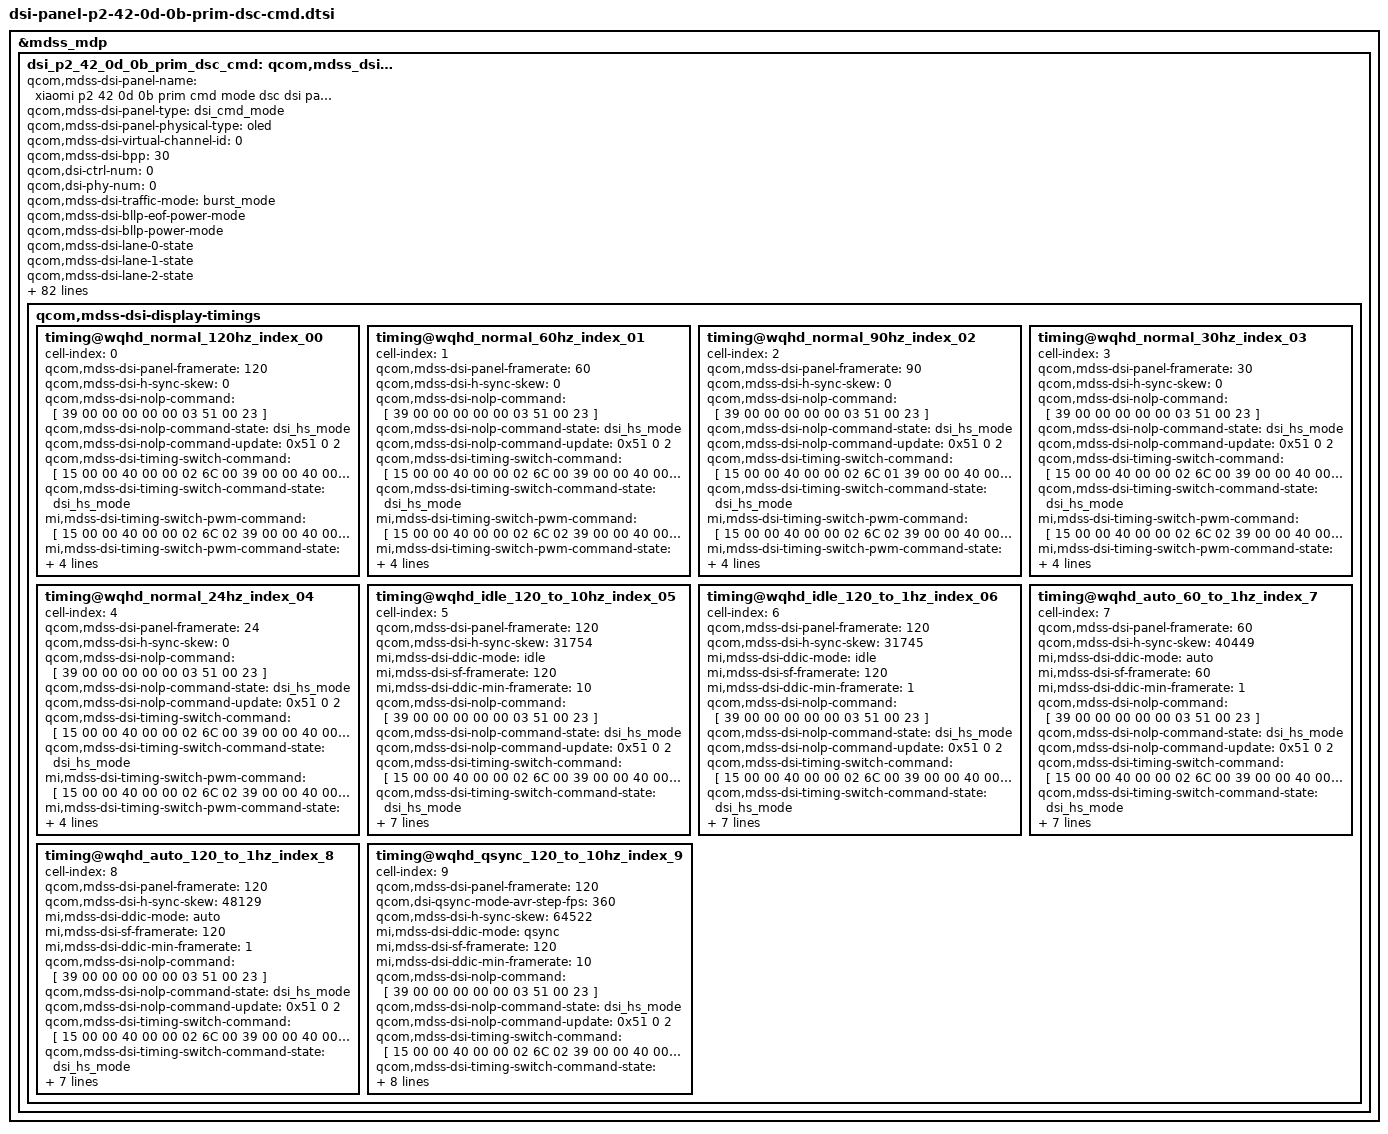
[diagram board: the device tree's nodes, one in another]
&mdss_mdp {
	dsi_p2_42_0d_0b_prim_dsc_cmd: qcom,mdss_dsi_p2_42_0d_0b_prim_dsc_cmd {
		qcom,mdss-dsi-panel-name = "xiaomi p2 42 0d 0b prim cmd mode dsc dsi panel";
		qcom,mdss-dsi-panel-type = "dsi_cmd_mode";
		qcom,mdss-dsi-panel-physical-type = "oled";
		qcom,mdss-dsi-virtual-channel-id = <0>;
		qcom,mdss-dsi-bpp = <30>;
		qcom,dsi-ctrl-num = <0>;
		qcom,dsi-phy-num = <0>;
		qcom,mdss-dsi-traffic-mode = "burst_mode";
		qcom,mdss-dsi-bllp-eof-power-mode;
		qcom,mdss-dsi-bllp-power-mode;
		qcom,mdss-dsi-lane-0-state;
		qcom,mdss-dsi-lane-1-state;
		qcom,mdss-dsi-lane-2-state;
		qcom,mdss-dsi-lane-3-state;
		qcom,mdss-dsi-color-order = "rgb_swap_rgb";
		qcom,mdss-dsi-dma-trigger = "trigger_sw";
		qcom,mdss-dsi-mdp-trigger = "none";
		qcom,mdss-dsi-reset-sequence =<1 1>, <0 1>, <1 10>;
		qcom,mdss-pan-physical-width-dimension = <727>;
		qcom,mdss-pan-physical-height-dimension = <1580>;
		qcom,mdss-dsi-te-pin-select = <1>;
		qcom,mdss-dsi-wr-mem-start = <0x2c>;
		qcom,mdss-dsi-wr-mem-continue = <0x3c>;
		qcom,mdss-dsi-te-dcs-command = <1>;
		qcom,mdss-dsi-tx-eot-append;
		qcom,mdss-dsi-lp11-init;
		qcom,mdss-dsi-bl-inverted-dbv;
		qcom,bl-update-flag = "delay_until_first_frame";
		qcom,mdss-dsi-panel-hdr-enabled;
		qcom,mdss-dsi-panel-hdr-color-primaries = <14500 15500 32000
			17000 15500 30000 8000 3000>;
		qcom,mdss-dsi-panel-peak-brightness = <32000000>;
		qcom,mdss-dsi-panel-blackness-level = <3230>;
		qcom,mdss-dsi-dma-schedule-line = <1>;
		qcom,mdss-dsi-dma-schedule-window = <50>;

		qcom,mdss-disable-cesta-hw-sleep;

		qcom,mdss-dsi-display-timings {
			timing@wqhd_normal_120hz_index_00 {
				#include "dsi-panel-p2-42-0d-0b-prim-dsc-cmd-common.dtsi"
				cell-index = <0>;
				qcom,mdss-dsi-panel-framerate = <120>;
				qcom,mdss-dsi-h-sync-skew = <0>;
				qcom,mdss-dsi-nolp-command = [
					39 00 00 00 00 00 03 51 00 23
				];
				qcom,mdss-dsi-nolp-command-state = "dsi_hs_mode";
				qcom,mdss-dsi-nolp-command-update = <0x51 0 2>;
				qcom,mdss-dsi-timing-switch-command = [
					15 00 00 40 00 00 02 6C 00
					39 00 00 40 00 00 03 75 00 00
					39 00 00 40 00 00 04 71 00 00 00
					39 00 00 40 00 00 03 F0 AA 16
					15 00 00 40 00 00 02 D0 00
					15 00 00 40 00 00 02 65 01
					15 00 00 40 00 00 02 D1 00
					15 00 00 40 00 00 02 D2 01
					15 00 00 40 00 00 02 76 00
					15 00 00 40 00 00 02 77 00
					39 00 00 40 00 00 03 F0 AA 10
					15 00 00 40 00 00 02 CF 17
					39 00 00 00 00 00 03 F0 AA 00
				];
				qcom,mdss-dsi-timing-switch-command-state = "dsi_hs_mode";
				mi,mdss-dsi-timing-switch-pwm-command = [
					15 00 00 40 00 00 02 6C 02
					39 00 00 40 00 00 03 75 00 00
					39 00 00 40 00 00 04 71 00 00 00
					39 00 00 40 00 00 03 F0 AA 16
					15 00 00 40 00 00 02 D0 00
					15 00 00 40 00 00 02 65 07
					15 00 00 40 00 00 02 D1 02
					15 00 00 40 00 00 02 D2 01
					15 00 00 40 00 00 02 65 02
					39 00 00 40 00 00 04 D2 03 65 0F
					15 00 00 40 00 00 02 76 01
					15 00 00 40 00 00 02 77 05
					39 00 00 40 00 00 03 F0 AA 10
					15 00 00 40 00 00 02 CF 09
					39 00 00 00 00 00 03 F0 AA 00
				];
				mi,mdss-dsi-timing-switch-pwm-command-state = "dsi_hs_mode";
				qcom,mdss-dsi-on-command = [
					15 00 00 40 00 00 02 00 00
					15 00 00 40 00 00 02 03 01
					15 00 00 40 00 00 02 35 00
					15 00 00 40 00 00 02 53 20
					39 00 00 40 00 00 03 51 00 00
					15 00 00 40 00 00 02 6F 02
					15 00 00 40 00 00 02 59 00
					15 00 00 40 00 00 02 6C 00
					15 00 00 40 00 00 02 6D 00
					39 00 00 40 00 00 5F 70 11 00 00 89 30 80 0a 30 04 b0
											00 10 02 58 02 58 02 00 02 2c
											00 20 01 98 00 08 00 0c 06 67
											05 b9 18 00 10 f0 03 0c 20 00
											06 0b 0b 33 0e 1c 2a 38 46 54
											62 69 70 77 79 7b 7d 7e 01 02
											01 00 09 40 09 be 19 fc 19 fa
											19 f8 1a 38 1a 78 1a b6 2a b6
											2a f4 2a f4 4b 34 63 74 00 00 00 00 00 00
					39 00 00 40 00 00 03 FF 5A 81
					15 00 00 40 00 00 02 65 03
					15 00 00 40 00 00 02 F3 04
					15 00 00 40 00 00 02 65 05
					15 00 00 40 00 00 02 F3 48
					39 00 00 40 00 00 03 F0 AA 10
					15 00 00 40 00 00 02 65 0A
					15 00 00 40 00 00 02 EB 10
					15 00 00 40 00 00 02 72 00
					39 00 00 40 00 00 03 F0 AA 18
					15 00 00 40 00 00 02 B0 80
					39 00 00 40 00 00 03 F0 AA 00
					39 00 00 40 00 00 03 FF 5A 00
					05 00 00 00 78 00 01 11
					39 00 00 40 00 00 03 F0 AA 10
					15 00 00 40 00 00 02 65 02
					39 00 00 40 00 00 03 CF 24 13
					15 00 00 40 00 00 02 65 0B
					15 00 00 40 00 00 02 CF FF
					39 00 00 00 00 00 03 F0 AA 00
					39 00 00 40 00 00 03 F0 AA 16
					39 00 00 40 00 00 16 E3 00 01 00 00 00 00 00 00 00 00 00 00 00 00 00 00 00 00 00 00 00
					39 00 00 40 00 00 16 E4 00 03 00 00 00 00 00 00 00 00 00 00 00 00 00 00 00 00 00 00 00
					39 00 00 40 00 00 16 E5 00 04 00 00 00 00 00 00 00 00 00 00 00 00 00 00 00 00 00 00 00
					39 00 00 40 00 00 16 E6 01 03 0B 00 00 00 00 00 00 00 00 00 00 00 00 00 00 00 00 00 00
					39 00 00 40 00 00 16 E7 03 03 0B 0B 77 00 00 00 00 0E E0 00 00 00 00 00 00 00 00 00 00
					39 00 00 40 00 00 16 E8 02 0B 0B 77 00 00 00 00 00 EE 00 00 00 00 00 00 00 00 00 00 00
					39 00 00 40 00 00 16 E9 02 08 08 59 00 00 00 00 00 EE 00 00 00 00 00 00 00 00 00 00 00
					39 00 00 40 00 00 16 EA 00 0B 00 00 00 00 00 00 00 00 00 00 00 00 00 00 00 00 00 00 00
					39 00 00 40 00 00 16 EB 02 01 03 EF 00 00 00 00 00 00 00 00 00 00 00 00 00 00 00 00 00
					39 00 00 40 00 00 16 EC 00 01 00 00 00 00 00 00 00 40 00 00 00 00 00 00 00 00 00 00 00
					39 00 00 40 00 00 1F E0 F0 F1 F2 F3 F4 F5 F6 00 00 00 F0 F1 F2 F3 F4 F5 F6 00 00 00 F0 F1 F2 F3 F4 F5 F6 00 00 00
					39 00 00 40 00 00 15 ED F0 F1 F2 F3 F4 F5 F6 F7 F8 00 F0 F1 F2 F3 F4 F5 F6 F7 F8 00
					39 00 00 00 00 00 15 EE F0 F1 F2 F3 F4 F5 F6 F7 F8 00 F0 F1 F2 F3 F4 F5 F6 F7 F8 00
					//Close ELVDD LVD
					39 00 00 40 00 00 03 F0 AA 12
					15 00 00 40 00 00 02 C7 FE
					05 00 00 00 00 00 01 29
					39 00 00 40 00 00 03 F0 AA 10
					15 00 00 40 00 00 02 65 0B
					39 00 00 40 00 00 03 CF DD 79
					39 00 00 00 00 00 03 F0 AA 00
					// FD open
					39 00 00 40 00 00 03 F0 AA 10
					15 00 00 40 00 00 02 D0 A4
					15 00 00 40 00 00 02 65 04
					15 00 00 40 00 00 02 D0 E6
					15 00 00 40 00 00 02 65 13
					39 00 00 00 24 00 03 D8 02 1F
					// FD close
					39 00 00 40 00 00 03 F0 AA 10
					15 00 00 40 00 00 02 D0 84
					39 00 00 00 00 00 03 F0 AA 00
				];
				qcom,mdss-dsi-on-command-state = "dsi_lp_mode";
			};
			timing@wqhd_normal_60hz_index_01 {
				#include "dsi-panel-p2-42-0d-0b-prim-dsc-cmd-common.dtsi"
				cell-index = <1>;
				qcom,mdss-dsi-panel-framerate = <60>;
				qcom,mdss-dsi-h-sync-skew = <0>;
				qcom,mdss-dsi-nolp-command = [
					39 00 00 00 00 00 03 51 00 23
				];
				qcom,mdss-dsi-nolp-command-state = "dsi_hs_mode";
				qcom,mdss-dsi-nolp-command-update = <0x51 0 2>;
				qcom,mdss-dsi-timing-switch-command = [
					15 00 00 40 00 00 02 6C 00
					39 00 00 40 00 00 03 75 C0 00
					39 00 00 40 00 00 04 71 01 00 01
					39 00 00 40 00 00 03 F0 AA 16
					15 00 00 40 00 00 02 D0 00
					15 00 00 40 00 00 02 65 01
					15 00 00 40 00 00 02 D1 00
					15 00 00 40 00 00 02 D2 01
					15 00 00 40 00 00 02 65 02
					39 00 00 40 00 00 04 D2 0A 53 0F
					15 00 00 40 00 00 02 76 01
					15 00 00 40 00 00 02 77 03
					39 00 00 40 00 00 03 F0 AA 10
					15 00 00 40 00 00 02 CF 09
					39 00 00 00 00 00 03 F0 AA 00
				];
				qcom,mdss-dsi-timing-switch-command-state = "dsi_hs_mode";
				mi,mdss-dsi-timing-switch-pwm-command = [
					15 00 00 40 00 00 02 6C 02
					39 00 00 40 00 00 03 75 C0 00
					39 00 00 40 00 00 04 71 01 00 01
					39 00 00 40 00 00 03 F0 AA 16
					15 00 00 40 00 00 02 D0 00
					15 00 00 40 00 00 02 65 07
					15 00 00 40 00 00 02 D1 02
					15 00 00 40 00 00 02 D2 01
					15 00 00 40 00 00 02 65 02
					39 00 00 40 00 00 04 D2 03 65 0F
					15 00 00 40 00 00 02 76 01
					15 00 00 40 00 00 02 77 0B
					39 00 00 40 00 00 03 F0 AA 10
					15 00 00 40 00 00 02 CF 09
					39 00 00 00 00 00 03 F0 AA 00
				];
				mi,mdss-dsi-timing-switch-pwm-command-state = "dsi_hs_mode";
				qcom,mdss-dsi-on-command = [
					15 00 00 40 00 00 02 00 00
					15 00 00 40 00 00 02 03 01
					15 00 00 40 00 00 02 35 00
					15 00 00 40 00 00 02 53 20
					39 00 00 40 00 00 03 51 00 00
					15 00 00 40 00 00 02 6F 02
					15 00 00 40 00 00 02 59 00
					15 00 00 40 00 00 02 6C 00
					15 00 00 40 00 00 02 6D 00
					39 00 00 40 00 00 5F 70 11 00 00 89 30 80 0a 30 04 b0
											00 10 02 58 02 58 02 00 02 2c
											00 20 01 98 00 08 00 0c 06 67
											05 b9 18 00 10 f0 03 0c 20 00
											06 0b 0b 33 0e 1c 2a 38 46 54
											62 69 70 77 79 7b 7d 7e 01 02
											01 00 09 40 09 be 19 fc 19 fa
											19 f8 1a 38 1a 78 1a b6 2a b6
											2a f4 2a f4 4b 34 63 74 00 00 00 00 00 00
					39 00 00 40 00 00 03 FF 5A 81
					15 00 00 40 00 00 02 65 03
					15 00 00 40 00 00 02 F3 04
					15 00 00 40 00 00 02 65 05
					15 00 00 40 00 00 02 F3 48
					39 00 00 40 00 00 03 F0 AA 10
					15 00 00 40 00 00 02 65 0A
					15 00 00 40 00 00 02 EB 10
					15 00 00 40 00 00 02 72 00
					39 00 00 40 00 00 03 F0 AA 18
					15 00 00 40 00 00 02 B0 80
					39 00 00 40 00 00 03 F0 AA 00
					39 00 00 40 00 00 03 FF 5A 00
					05 00 00 00 78 00 01 11
					39 00 00 40 00 00 03 F0 AA 10
					15 00 00 40 00 00 02 65 02
					39 00 00 40 00 00 03 CF 24 13
					15 00 00 40 00 00 02 65 0B
					15 00 00 40 00 00 02 CF FF
					39 00 00 00 00 00 03 F0 AA 00
					39 00 00 40 00 00 03 F0 AA 16
					39 00 00 40 00 00 16 E3 00 01 00 00 00 00 00 00 00 00 00 00 00 00 00 00 00 00 00 00 00
					39 00 00 40 00 00 16 E4 00 03 00 00 00 00 00 00 00 00 00 00 00 00 00 00 00 00 00 00 00
					39 00 00 40 00 00 16 E5 00 04 00 00 00 00 00 00 00 00 00 00 00 00 00 00 00 00 00 00 00
					39 00 00 40 00 00 16 E6 01 03 0B 00 00 00 00 00 00 00 00 00 00 00 00 00 00 00 00 00 00
					39 00 00 40 00 00 16 E7 03 03 0B 0B 77 00 00 00 00 0E E0 00 00 00 00 00 00 00 00 00 00
					39 00 00 40 00 00 16 E8 02 0B 0B 77 00 00 00 00 00 EE 00 00 00 00 00 00 00 00 00 00 00
					39 00 00 40 00 00 16 E9 02 08 08 59 00 00 00 00 00 EE 00 00 00 00 00 00 00 00 00 00 00
					39 00 00 40 00 00 16 EA 00 0B 00 00 00 00 00 00 00 00 00 00 00 00 00 00 00 00 00 00 00
					39 00 00 40 00 00 16 EB 02 01 03 EF 00 00 00 00 00 00 00 00 00 00 00 00 00 00 00 00 00
					39 00 00 40 00 00 16 EC 00 01 00 00 00 00 00 00 00 40 00 00 00 00 00 00 00 00 00 00 00
					39 00 00 40 00 00 1F E0 F0 F1 F2 F3 F4 F5 F6 00 00 00 F0 F1 F2 F3 F4 F5 F6 00 00 00 F0 F1 F2 F3 F4 F5 F6 00 00 00
					39 00 00 40 00 00 15 ED F0 F1 F2 F3 F4 F5 F6 F7 F8 00 F0 F1 F2 F3 F4 F5 F6 F7 F8 00
					39 00 00 00 00 00 15 EE F0 F1 F2 F3 F4 F5 F6 F7 F8 00 F0 F1 F2 F3 F4 F5 F6 F7 F8 00
					//Close ELVDD LVD
					39 00 00 40 00 00 03 F0 AA 12
					15 00 00 40 00 00 02 C7 FE
					05 00 00 00 00 00 01 29
					39 00 00 40 00 00 03 F0 AA 10
					15 00 00 40 00 00 02 65 0B
					39 00 00 40 00 00 03 CF DD 79
					39 00 00 00 00 00 03 F0 AA 00
					// FD open
					39 00 00 40 00 00 03 F0 AA 10
					15 00 00 40 00 00 02 D0 A4
					15 00 00 40 00 00 02 65 04
					15 00 00 40 00 00 02 D0 E6
					15 00 00 40 00 00 02 65 13
					39 00 00 00 24 00 03 D8 02 1F
					// FD close
					39 00 00 40 00 00 03 F0 AA 10
					15 00 00 40 00 00 02 D0 84
					39 00 00 00 00 00 03 F0 AA 00
				];
				qcom,mdss-dsi-on-command-state = "dsi_lp_mode";
			};
			timing@wqhd_normal_90hz_index_02 {
				#include "dsi-panel-p2-42-0d-0b-prim-dsc-cmd-common.dtsi"
				cell-index = <2>;
				qcom,mdss-dsi-panel-framerate = <90>;
				qcom,mdss-dsi-h-sync-skew = <0>;
				qcom,mdss-dsi-nolp-command = [
					39 00 00 00 00 00 03 51 00 23
				];
				qcom,mdss-dsi-nolp-command-state = "dsi_hs_mode";
				qcom,mdss-dsi-nolp-command-update = <0x51 0 2>;
				qcom,mdss-dsi-timing-switch-command = [
					15 00 00 40 00 00 02 6C 01
					39 00 00 40 00 00 03 75 C0 06
					39 00 00 40 00 00 04 71 00 00 00
					39 00 00 40 00 00 03 F0 AA 16
					15 00 00 40 00 00 02 D0 03
					15 00 00 40 00 00 02 65 04
					15 00 00 40 00 00 02 D1 02
					15 00 00 40 00 00 02 D2 01
					15 00 00 40 00 00 02 65 02
					39 00 00 40 00 00 04 D2 0D CA 0F
					15 00 00 40 00 00 02 76 01
					15 00 00 40 00 00 02 77 01
					39 00 00 40 00 00 03 F0 AA 10
					15 00 00 40 00 00 02 CF 09
					39 00 00 00 00 00 03 F0 AA 00
				];
				qcom,mdss-dsi-timing-switch-command-state = "dsi_hs_mode";
				mi,mdss-dsi-timing-switch-pwm-command = [
					15 00 00 40 00 00 02 6C 02
					39 00 00 40 00 00 03 75 C0 00
					39 00 00 40 00 00 04 71 01 10 00
					39 00 00 40 00 00 03 F0 AA 16
					15 00 00 40 00 00 02 D0 00
					15 00 00 40 00 00 02 65 07
					15 00 00 40 00 00 02 D1 02
					15 00 00 40 00 00 02 D2 01
					15 00 00 40 00 00 02 65 02
					39 00 00 40 00 00 04 D2 03 65 0F
					15 00 00 40 00 00 02 76 01
					15 00 00 40 00 00 02 77 07
					39 00 00 40 00 00 03 F0 AA 10
					15 00 00 40 00 00 02 CF 09
					39 00 00 00 00 00 03 F0 AA 00
				];
				mi,mdss-dsi-timing-switch-pwm-command-state = "dsi_hs_mode";
				qcom,mdss-dsi-on-command = [
					15 00 00 40 00 00 02 00 00
					15 00 00 40 00 00 02 03 01
					15 00 00 40 00 00 02 35 00
					15 00 00 40 00 00 02 53 20
					39 00 00 40 00 00 03 51 00 00
					15 00 00 40 00 00 02 6F 02
					15 00 00 40 00 00 02 59 00
					15 00 00 40 00 00 02 6C 00
					15 00 00 40 00 00 02 6D 00
					39 00 00 40 00 00 5F 70 11 00 00 89 30 80 0a 30 04 b0
											00 10 02 58 02 58 02 00 02 2c
											00 20 01 98 00 08 00 0c 06 67
											05 b9 18 00 10 f0 03 0c 20 00
											06 0b 0b 33 0e 1c 2a 38 46 54
											62 69 70 77 79 7b 7d 7e 01 02
											01 00 09 40 09 be 19 fc 19 fa
											19 f8 1a 38 1a 78 1a b6 2a b6
											2a f4 2a f4 4b 34 63 74 00 00 00 00 00 00
					39 00 00 40 00 00 03 FF 5A 81
					15 00 00 40 00 00 02 65 03
					15 00 00 40 00 00 02 F3 04
					15 00 00 40 00 00 02 65 05
					15 00 00 40 00 00 02 F3 48
					39 00 00 40 00 00 03 F0 AA 10
					15 00 00 40 00 00 02 65 0A
					15 00 00 40 00 00 02 EB 10
					15 00 00 40 00 00 02 72 00
					39 00 00 40 00 00 03 F0 AA 18
					15 00 00 40 00 00 02 B0 80
					39 00 00 40 00 00 03 F0 AA 00
					39 00 00 40 00 00 03 FF 5A 00
					05 00 00 00 78 00 01 11
					39 00 00 40 00 00 03 F0 AA 10
					15 00 00 40 00 00 02 65 02
					39 00 00 40 00 00 03 CF 24 13
					15 00 00 40 00 00 02 65 0B
					15 00 00 40 00 00 02 CF FF
					39 00 00 00 00 00 03 F0 AA 00
					39 00 00 40 00 00 03 F0 AA 16
					39 00 00 40 00 00 16 E3 00 01 00 00 00 00 00 00 00 00 00 00 00 00 00 00 00 00 00 00 00
					39 00 00 40 00 00 16 E4 00 03 00 00 00 00 00 00 00 00 00 00 00 00 00 00 00 00 00 00 00
					39 00 00 40 00 00 16 E5 00 04 00 00 00 00 00 00 00 00 00 00 00 00 00 00 00 00 00 00 00
					39 00 00 40 00 00 16 E6 01 03 0B 00 00 00 00 00 00 00 00 00 00 00 00 00 00 00 00 00 00
					39 00 00 40 00 00 16 E7 03 03 0B 0B 77 00 00 00 00 0E E0 00 00 00 00 00 00 00 00 00 00
					39 00 00 40 00 00 16 E8 02 0B 0B 77 00 00 00 00 00 EE 00 00 00 00 00 00 00 00 00 00 00
					39 00 00 40 00 00 16 E9 02 08 08 59 00 00 00 00 00 EE 00 00 00 00 00 00 00 00 00 00 00
					39 00 00 40 00 00 16 EA 00 0B 00 00 00 00 00 00 00 00 00 00 00 00 00 00 00 00 00 00 00
					39 00 00 40 00 00 16 EB 02 01 03 EF 00 00 00 00 00 00 00 00 00 00 00 00 00 00 00 00 00
					39 00 00 40 00 00 16 EC 00 01 00 00 00 00 00 00 00 40 00 00 00 00 00 00 00 00 00 00 00
					39 00 00 40 00 00 1F E0 F0 F1 F2 F3 F4 F5 F6 00 00 00 F0 F1 F2 F3 F4 F5 F6 00 00 00 F0 F1 F2 F3 F4 F5 F6 00 00 00
					39 00 00 40 00 00 15 ED F0 F1 F2 F3 F4 F5 F6 F7 F8 00 F0 F1 F2 F3 F4 F5 F6 F7 F8 00
					39 00 00 00 00 00 15 EE F0 F1 F2 F3 F4 F5 F6 F7 F8 00 F0 F1 F2 F3 F4 F5 F6 F7 F8 00
					//Close ELVDD LVD
					39 00 00 40 00 00 03 F0 AA 12
					15 00 00 40 00 00 02 C7 FE
					05 00 00 00 00 00 01 29
					39 00 00 40 00 00 03 F0 AA 10
					15 00 00 40 00 00 02 65 0B
					39 00 00 40 00 00 03 CF DD 79
					39 00 00 00 00 00 03 F0 AA 00
					// FD open
					39 00 00 40 00 00 03 F0 AA 10
					15 00 00 40 00 00 02 D0 A4
					15 00 00 40 00 00 02 65 04
					15 00 00 40 00 00 02 D0 E6
					15 00 00 40 00 00 02 65 13
					39 00 00 00 24 00 03 D8 02 1F
					// FD close
					39 00 00 40 00 00 03 F0 AA 10
					15 00 00 40 00 00 02 D0 84
					39 00 00 00 00 00 03 F0 AA 00
				];
				qcom,mdss-dsi-on-command-state = "dsi_lp_mode";
			};
			timing@wqhd_normal_30hz_index_03 {
				#include "dsi-panel-p2-42-0d-0b-prim-dsc-cmd-common.dtsi"
				cell-index = <3>;
				qcom,mdss-dsi-panel-framerate = <30>;
				qcom,mdss-dsi-h-sync-skew = <0>;
				qcom,mdss-dsi-nolp-command = [
					39 00 00 00 00 00 03 51 00 23
				];
				qcom,mdss-dsi-nolp-command-state = "dsi_hs_mode";
				qcom,mdss-dsi-nolp-command-update = <0x51 0 2>;
				qcom,mdss-dsi-timing-switch-command = [
					15 00 00 40 00 00 02 6C 00
					39 00 00 40 00 00 03 75 C0 01
					39 00 00 40 00 00 04 71 00 00 00
					39 00 00 40 00 00 03 F0 AA 16
					15 00 00 40 00 00 02 D0 00
					15 00 00 40 00 00 02 65 01
					15 00 00 40 00 00 02 D1 01
					15 00 00 40 00 00 02 D2 01
					15 00 00 40 00 00 02 65 02
					39 00 00 40 00 00 04 D2 0A 53 0F
					15 00 00 40 00 00 02 76 01
					15 00 00 40 00 00 02 77 07
					39 00 00 40 00 00 03 F0 AA 10
					15 00 00 40 00 00 02 CF 09
					39 00 00 00 00 00 03 F0 AA 00
				];
				qcom,mdss-dsi-timing-switch-command-state = "dsi_hs_mode";
				mi,mdss-dsi-timing-switch-pwm-command = [
					15 00 00 40 00 00 02 6C 02
					39 00 00 40 00 00 03 75 C0 01
					39 00 00 40 00 00 04 71 00 00 00
					39 00 00 40 00 00 03 F0 AA 16
					15 00 00 40 00 00 02 D0 00
					15 00 00 40 00 00 02 65 07
					15 00 00 40 00 00 02 D1 05
					15 00 00 40 00 00 02 D2 01
					15 00 00 40 00 00 02 65 02
					39 00 00 40 00 00 04 D2 03 65 0F
					15 00 00 40 00 00 02 76 01
					15 00 00 40 00 00 02 77 17
					39 00 00 40 00 00 03 F0 AA 10
					15 00 00 40 00 00 02 CF 09
					39 00 00 00 00 00 03 F0 AA 00
				];
				mi,mdss-dsi-timing-switch-pwm-command-state = "dsi_hs_mode";
				qcom,mdss-dsi-on-command = [
					15 00 00 40 00 00 02 00 00
					15 00 00 40 00 00 02 03 01
					15 00 00 40 00 00 02 35 00
					15 00 00 40 00 00 02 53 20
					39 00 00 40 00 00 03 51 00 00
					15 00 00 40 00 00 02 6F 02
					15 00 00 40 00 00 02 59 00
					15 00 00 40 00 00 02 6C 00
					15 00 00 40 00 00 02 6D 00
					39 00 00 40 00 00 5F 70 11 00 00 89 30 80 0a 30 04 b0
											00 10 02 58 02 58 02 00 02 2c
											00 20 01 98 00 08 00 0c 06 67
											05 b9 18 00 10 f0 03 0c 20 00
											06 0b 0b 33 0e 1c 2a 38 46 54
											62 69 70 77 79 7b 7d 7e 01 02
											01 00 09 40 09 be 19 fc 19 fa
											19 f8 1a 38 1a 78 1a b6 2a b6
											2a f4 2a f4 4b 34 63 74 00 00 00 00 00 00
					39 00 00 40 00 00 03 FF 5A 81
					15 00 00 40 00 00 02 65 03
					15 00 00 40 00 00 02 F3 04
					15 00 00 40 00 00 02 65 05
					15 00 00 40 00 00 02 F3 48
					39 00 00 40 00 00 03 F0 AA 10
					15 00 00 40 00 00 02 65 0A
					15 00 00 40 00 00 02 EB 10
					15 00 00 40 00 00 02 72 00
					39 00 00 40 00 00 03 F0 AA 18
					15 00 00 40 00 00 02 B0 80
					39 00 00 40 00 00 03 F0 AA 00
					39 00 00 40 00 00 03 FF 5A 00
					05 00 00 00 78 00 01 11
					39 00 00 40 00 00 03 F0 AA 10
					15 00 00 40 00 00 02 65 02
					39 00 00 40 00 00 03 CF 24 13
					15 00 00 40 00 00 02 65 0B
					15 00 00 40 00 00 02 CF FF
					39 00 00 00 00 00 03 F0 AA 00
					39 00 00 40 00 00 03 F0 AA 16
					39 00 00 40 00 00 16 E3 00 01 00 00 00 00 00 00 00 00 00 00 00 00 00 00 00 00 00 00 00
					39 00 00 40 00 00 16 E4 00 03 00 00 00 00 00 00 00 00 00 00 00 00 00 00 00 00 00 00 00
					39 00 00 40 00 00 16 E5 00 04 00 00 00 00 00 00 00 00 00 00 00 00 00 00 00 00 00 00 00
					39 00 00 40 00 00 16 E6 01 03 0B 00 00 00 00 00 00 00 00 00 00 00 00 00 00 00 00 00 00
					39 00 00 40 00 00 16 E7 03 03 0B 0B 77 00 00 00 00 0E E0 00 00 00 00 00 00 00 00 00 00
					39 00 00 40 00 00 16 E8 02 0B 0B 77 00 00 00 00 00 EE 00 00 00 00 00 00 00 00 00 00 00
					39 00 00 40 00 00 16 E9 02 08 08 59 00 00 00 00 00 EE 00 00 00 00 00 00 00 00 00 00 00
					39 00 00 40 00 00 16 EA 00 0B 00 00 00 00 00 00 00 00 00 00 00 00 00 00 00 00 00 00 00
					39 00 00 40 00 00 16 EB 02 01 03 EF 00 00 00 00 00 00 00 00 00 00 00 00 00 00 00 00 00
					39 00 00 40 00 00 16 EC 00 01 00 00 00 00 00 00 00 40 00 00 00 00 00 00 00 00 00 00 00
					39 00 00 40 00 00 1F E0 F0 F1 F2 F3 F4 F5 F6 00 00 00 F0 F1 F2 F3 F4 F5 F6 00 00 00 F0 F1 F2 F3 F4 F5 F6 00 00 00
					39 00 00 40 00 00 15 ED F0 F1 F2 F3 F4 F5 F6 F7 F8 00 F0 F1 F2 F3 F4 F5 F6 F7 F8 00
					39 00 00 00 00 00 15 EE F0 F1 F2 F3 F4 F5 F6 F7 F8 00 F0 F1 F2 F3 F4 F5 F6 F7 F8 00
					//Close ELVDD LVD
					39 00 00 40 00 00 03 F0 AA 12
					15 00 00 40 00 00 02 C7 FE
					05 00 00 00 00 00 01 29
					39 00 00 40 00 00 03 F0 AA 10
					15 00 00 40 00 00 02 65 0B
					39 00 00 40 00 00 03 CF DD 79
					39 00 00 00 00 00 03 F0 AA 00
					// FD open
					39 00 00 40 00 00 03 F0 AA 10
					15 00 00 40 00 00 02 D0 A4
					15 00 00 40 00 00 02 65 04
					15 00 00 40 00 00 02 D0 E6
					15 00 00 40 00 00 02 65 13
					39 00 00 00 24 00 03 D8 02 1F
					// FD close
					39 00 00 40 00 00 03 F0 AA 10
					15 00 00 40 00 00 02 D0 84
					39 00 00 00 00 00 03 F0 AA 00
				];
				qcom,mdss-dsi-on-command-state = "dsi_lp_mode";
			};
			timing@wqhd_normal_24hz_index_04 {
				#include "dsi-panel-p2-42-0d-0b-prim-dsc-cmd-common.dtsi"
				cell-index = <4>;
				qcom,mdss-dsi-panel-framerate = <24>;
				qcom,mdss-dsi-h-sync-skew = <0>;
				qcom,mdss-dsi-nolp-command = [
					39 00 00 00 00 00 03 51 00 23
				];
				qcom,mdss-dsi-nolp-command-state = "dsi_hs_mode";
				qcom,mdss-dsi-nolp-command-update = <0x51 0 2>;
				qcom,mdss-dsi-timing-switch-command = [
					15 00 00 40 00 00 02 6C 00
					39 00 00 40 00 00 03 75 C0 02
					39 00 00 40 00 00 04 71 00 00 00
					39 00 00 40 00 00 03 F0 AA 16
					15 00 00 40 00 00 02 D0 00
					15 00 00 40 00 00 02 65 01
					15 00 00 40 00 00 02 D1 01
					15 00 00 40 00 00 02 D2 01
					15 00 00 40 00 00 02 65 02
					39 00 00 40 00 00 04 D2 0A 53 0F
					15 00 00 40 00 00 02 76 01
					15 00 00 40 00 00 02 77 09
					39 00 00 40 00 00 03 F0 AA 10
					15 00 00 40 00 00 02 CF 09
					39 00 00 00 00 00 03 F0 AA 00
				];
				qcom,mdss-dsi-timing-switch-command-state = "dsi_hs_mode";
				mi,mdss-dsi-timing-switch-pwm-command = [
					15 00 00 40 00 00 02 6C 02
					39 00 00 40 00 00 03 75 C0 02
					39 00 00 40 00 00 04 71 00 00 00
					39 00 00 40 00 00 03 F0 AA 16
					15 00 00 40 00 00 02 D0 00
					15 00 00 40 00 00 02 65 07
					15 00 00 40 00 00 02 D1 0B
					15 00 00 40 00 00 02 D2 01
					15 00 00 40 00 00 02 65 02
					39 00 00 40 00 00 04 D2 03 65 0F
					15 00 00 40 00 00 02 76 01
					15 00 00 40 00 00 02 77 1D
					39 00 00 40 00 00 03 F0 AA 10
					15 00 00 40 00 00 02 CF 09
					39 00 00 00 00 00 03 F0 AA 00
				];
				mi,mdss-dsi-timing-switch-pwm-command-state = "dsi_hs_mode";
				qcom,mdss-dsi-on-command = [
					15 00 00 40 00 00 02 00 00
					15 00 00 40 00 00 02 03 01
					15 00 00 40 00 00 02 35 00
					15 00 00 40 00 00 02 53 20
					39 00 00 40 00 00 03 51 00 00
					15 00 00 40 00 00 02 6F 02
					15 00 00 40 00 00 02 59 00
					15 00 00 40 00 00 02 6C 00
					15 00 00 40 00 00 02 6D 00
					39 00 00 40 00 00 5F 70 11 00 00 89 30 80 0a 30 04 b0
											00 10 02 58 02 58 02 00 02 2c
											00 20 01 98 00 08 00 0c 06 67
											05 b9 18 00 10 f0 03 0c 20 00
											06 0b 0b 33 0e 1c 2a 38 46 54
											62 69 70 77 79 7b 7d 7e 01 02
											01 00 09 40 09 be 19 fc 19 fa
											19 f8 1a 38 1a 78 1a b6 2a b6
											2a f4 2a f4 4b 34 63 74 00 00 00 00 00 00
					39 00 00 40 00 00 03 FF 5A 81
					15 00 00 40 00 00 02 65 03
					15 00 00 40 00 00 02 F3 04
					15 00 00 40 00 00 02 65 05
					15 00 00 40 00 00 02 F3 48
					39 00 00 40 00 00 03 F0 AA 10
					15 00 00 40 00 00 02 65 0A
					15 00 00 40 00 00 02 EB 10
					15 00 00 40 00 00 02 72 00
					39 00 00 40 00 00 03 F0 AA 18
					15 00 00 40 00 00 02 B0 80
					39 00 00 40 00 00 03 F0 AA 00
					39 00 00 40 00 00 03 FF 5A 00
					05 00 00 00 78 00 01 11
					39 00 00 40 00 00 03 F0 AA 10
					15 00 00 40 00 00 02 65 02
					39 00 00 40 00 00 03 CF 24 13
					15 00 00 40 00 00 02 65 0B
					15 00 00 40 00 00 02 CF FF
					39 00 00 00 00 00 03 F0 AA 00
					39 00 00 40 00 00 03 F0 AA 16
					39 00 00 40 00 00 16 E3 00 01 00 00 00 00 00 00 00 00 00 00 00 00 00 00 00 00 00 00 00
					39 00 00 40 00 00 16 E4 00 03 00 00 00 00 00 00 00 00 00 00 00 00 00 00 00 00 00 00 00
					39 00 00 40 00 00 16 E5 00 04 00 00 00 00 00 00 00 00 00 00 00 00 00 00 00 00 00 00 00
					39 00 00 40 00 00 16 E6 01 03 0B 00 00 00 00 00 00 00 00 00 00 00 00 00 00 00 00 00 00
					39 00 00 40 00 00 16 E7 03 03 0B 0B 77 00 00 00 00 0E E0 00 00 00 00 00 00 00 00 00 00
					39 00 00 40 00 00 16 E8 02 0B 0B 77 00 00 00 00 00 EE 00 00 00 00 00 00 00 00 00 00 00
					39 00 00 40 00 00 16 E9 02 08 08 59 00 00 00 00 00 EE 00 00 00 00 00 00 00 00 00 00 00
					39 00 00 40 00 00 16 EA 00 0B 00 00 00 00 00 00 00 00 00 00 00 00 00 00 00 00 00 00 00
					39 00 00 40 00 00 16 EB 02 01 03 EF 00 00 00 00 00 00 00 00 00 00 00 00 00 00 00 00 00
					39 00 00 40 00 00 16 EC 00 01 00 00 00 00 00 00 00 40 00 00 00 00 00 00 00 00 00 00 00
					39 00 00 40 00 00 1F E0 F0 F1 F2 F3 F4 F5 F6 00 00 00 F0 F1 F2 F3 F4 F5 F6 00 00 00 F0 F1 F2 F3 F4 F5 F6 00 00 00
					39 00 00 40 00 00 15 ED F0 F1 F2 F3 F4 F5 F6 F7 F8 00 F0 F1 F2 F3 F4 F5 F6 F7 F8 00
					39 00 00 00 00 00 15 EE F0 F1 F2 F3 F4 F5 F6 F7 F8 00 F0 F1 F2 F3 F4 F5 F6 F7 F8 00
					//Close ELVDD LVD
					39 00 00 40 00 00 03 F0 AA 12
					15 00 00 40 00 00 02 C7 FE
					05 00 00 00 00 00 01 29
					39 00 00 40 00 00 03 F0 AA 10
					15 00 00 40 00 00 02 65 0B
					39 00 00 40 00 00 03 CF DD 79
					39 00 00 00 00 00 03 F0 AA 00
					// FD open
					39 00 00 40 00 00 03 F0 AA 10
					15 00 00 40 00 00 02 D0 A4
					15 00 00 40 00 00 02 65 04
					15 00 00 40 00 00 02 D0 E6
					15 00 00 40 00 00 02 65 13
					39 00 00 00 24 00 03 D8 02 1F
					// FD close
					39 00 00 40 00 00 03 F0 AA 10
					15 00 00 40 00 00 02 D0 84
					39 00 00 00 00 00 03 F0 AA 00
				];
				qcom,mdss-dsi-on-command-state = "dsi_lp_mode";
			};
			timing@wqhd_idle_120_to_10hz_index_05 {
				#include "dsi-panel-p2-42-0d-0b-prim-dsc-cmd-common.dtsi"
				cell-index = <5>;
				qcom,mdss-dsi-panel-framerate = <120>;
				/* ---------------------------- */
				/* | 15 - 14 | 13 - 7 | 6 - 0 | */
				/* ---------------------------- */
				/* |   mode  | sf fps | min fps| */
				/* ---------------------------- -*/
				/* mode: 1 idle, 2 auto, 3 qsync */
				/*   1 << 14 | 120 << 7 | 10     */
				qcom,mdss-dsi-h-sync-skew = <31754>;
				/* mode: 0 normal, 1 idle, 2 auto, 3 qsync, 4 diff, 5 test */
				mi,mdss-dsi-ddic-mode = "idle";
				mi,mdss-dsi-sf-framerate = <120>;
				mi,mdss-dsi-ddic-min-framerate = <10>;
				qcom,mdss-dsi-nolp-command = [
					39 00 00 00 00 00 03 51 00 23
				];
				qcom,mdss-dsi-nolp-command-state = "dsi_hs_mode";
				qcom,mdss-dsi-nolp-command-update = <0x51 0 2>;
				qcom,mdss-dsi-timing-switch-command = [
					15 00 00 40 00 00 02 6C 00
					39 00 00 40 00 00 03 75 C0 03
					39 00 00 40 00 00 04 71 00 00 00
					39 00 00 40 00 00 03 F0 AA 16
					15 00 00 40 00 00 02 D0 03
					15 00 00 40 00 00 02 65 01
					15 00 00 40 00 00 02 D1 01
					15 00 00 40 00 00 02 D2 01
					15 00 00 40 00 00 02 65 02
					39 00 00 40 00 00 04 D2 0A 53 0F
					15 00 00 40 00 00 02 76 01
					15 00 00 40 00 00 02 77 01
					39 00 00 40 00 00 03 F0 AA 10
					15 00 00 40 00 00 02 CF 09
					39 00 00 00 00 00 03 F0 AA 00
				];
				qcom,mdss-dsi-timing-switch-command-state = "dsi_hs_mode";
				mi,mdss-dsi-timing-switch-pwm-command = [
					15 00 00 40 00 00 02 6C 02
					39 00 00 40 00 00 03 75 C0 07
					39 00 00 40 00 00 04 71 00 00 00
					39 00 00 40 00 00 03 F0 AA 16
					15 00 00 40 00 00 02 D0 03
					15 00 00 40 00 00 02 65 07
					15 00 00 40 00 00 02 D1 0B
					15 00 00 40 00 00 02 D2 01
					15 00 00 40 00 00 02 65 02
					39 00 00 40 00 00 04 D2 03 65 0F
					15 00 00 40 00 00 02 76 01
					15 00 00 40 00 00 02 77 05
					39 00 00 40 00 00 03 F0 AA 10
					15 00 00 40 00 00 02 CF 09
					39 00 00 00 00 00 03 F0 AA 00
				];
				mi,mdss-dsi-timing-switch-pwm-command-state = "dsi_hs_mode";
				qcom,mdss-dsi-on-command = [
					15 00 00 40 00 00 02 00 00
					15 00 00 40 00 00 02 03 01
					15 00 00 40 00 00 02 35 00
					15 00 00 40 00 00 02 53 20
					39 00 00 40 00 00 03 51 00 00
					15 00 00 40 00 00 02 6F 02
					15 00 00 40 00 00 02 59 00
					15 00 00 40 00 00 02 6C 00
					15 00 00 40 00 00 02 6D 00
					39 00 00 40 00 00 5F 70 11 00 00 89 30 80 0a 30 04 b0
											00 10 02 58 02 58 02 00 02 2c
											00 20 01 98 00 08 00 0c 06 67
											05 b9 18 00 10 f0 03 0c 20 00
											06 0b 0b 33 0e 1c 2a 38 46 54
											62 69 70 77 79 7b 7d 7e 01 02
											01 00 09 40 09 be 19 fc 19 fa
											19 f8 1a 38 1a 78 1a b6 2a b6
											2a f4 2a f4 4b 34 63 74 00 00 00 00 00 00
					39 00 00 40 00 00 03 FF 5A 81
					15 00 00 40 00 00 02 65 03
					15 00 00 40 00 00 02 F3 04
					15 00 00 40 00 00 02 65 05
					15 00 00 40 00 00 02 F3 48
					39 00 00 40 00 00 03 F0 AA 10
					15 00 00 40 00 00 02 65 0A
					15 00 00 40 00 00 02 EB 10
					15 00 00 40 00 00 02 72 00
					39 00 00 40 00 00 03 F0 AA 18
					15 00 00 40 00 00 02 B0 80
					39 00 00 40 00 00 03 F0 AA 00
					39 00 00 40 00 00 03 FF 5A 00
					05 00 00 00 78 00 01 11
					39 00 00 40 00 00 03 F0 AA 10
					15 00 00 40 00 00 02 65 02
					39 00 00 40 00 00 03 CF 24 13
					15 00 00 40 00 00 02 65 0B
					15 00 00 40 00 00 02 CF FF
					39 00 00 00 00 00 03 F0 AA 00
					39 00 00 40 00 00 03 F0 AA 16
					39 00 00 40 00 00 16 E3 00 01 00 00 00 00 00 00 00 00 00 00 00 00 00 00 00 00 00 00 00
					39 00 00 40 00 00 16 E4 00 03 00 00 00 00 00 00 00 00 00 00 00 00 00 00 00 00 00 00 00
					39 00 00 40 00 00 16 E5 00 04 00 00 00 00 00 00 00 00 00 00 00 00 00 00 00 00 00 00 00
					39 00 00 40 00 00 16 E6 01 03 0B 00 00 00 00 00 00 00 00 00 00 00 00 00 00 00 00 00 00
					39 00 00 40 00 00 16 E7 03 03 0B 0B 77 00 00 00 00 0E E0 00 00 00 00 00 00 00 00 00 00
					39 00 00 40 00 00 16 E8 02 0B 0B 77 00 00 00 00 00 EE 00 00 00 00 00 00 00 00 00 00 00
					39 00 00 40 00 00 16 E9 02 08 08 59 00 00 00 00 00 EE 00 00 00 00 00 00 00 00 00 00 00
					39 00 00 40 00 00 16 EA 00 0B 00 00 00 00 00 00 00 00 00 00 00 00 00 00 00 00 00 00 00
					39 00 00 40 00 00 16 EB 02 01 03 EF 00 00 00 00 00 00 00 00 00 00 00 00 00 00 00 00 00
					39 00 00 40 00 00 16 EC 00 01 00 00 00 00 00 00 00 40 00 00 00 00 00 00 00 00 00 00 00
					39 00 00 40 00 00 1F E0 F0 F1 F2 F3 F4 F5 F6 00 00 00 F0 F1 F2 F3 F4 F5 F6 00 00 00 F0 F1 F2 F3 F4 F5 F6 00 00 00
					39 00 00 40 00 00 15 ED F0 F1 F2 F3 F4 F5 F6 F7 F8 00 F0 F1 F2 F3 F4 F5 F6 F7 F8 00
					39 00 00 00 00 00 15 EE F0 F1 F2 F3 F4 F5 F6 F7 F8 00 F0 F1 F2 F3 F4 F5 F6 F7 F8 00
					//Close ELVDD LVD
					39 00 00 40 00 00 03 F0 AA 12
					15 00 00 40 00 00 02 C7 FE
					05 00 00 00 00 00 01 29
					39 00 00 40 00 00 03 F0 AA 10
					15 00 00 40 00 00 02 65 0B
					39 00 00 40 00 00 03 CF DD 79
					39 00 00 00 00 00 03 F0 AA 00
					// FD open
					39 00 00 40 00 00 03 F0 AA 10
					15 00 00 40 00 00 02 D0 A4
					15 00 00 40 00 00 02 65 04
					15 00 00 40 00 00 02 D0 E6
					15 00 00 40 00 00 02 65 13
					39 00 00 00 24 00 03 D8 02 1F
					// FD close
					39 00 00 40 00 00 03 F0 AA 10
					15 00 00 40 00 00 02 D0 84
					39 00 00 00 00 00 03 F0 AA 00
				];
				qcom,mdss-dsi-on-command-state = "dsi_lp_mode";
			};
			timing@wqhd_idle_120_to_1hz_index_06 {
				#include "dsi-panel-p2-42-0d-0b-prim-dsc-cmd-common.dtsi"
				cell-index = <6>;
				qcom,mdss-dsi-panel-framerate = <120>;
				/* ---------------------------- */
				/* | 15 - 14 | 13 - 7 | 6 - 0 | */
				/* ---------------------------- */
				/* |   mode  | sf fps | min fps| */
				/* ---------------------------- -*/
				/* mode: 1 idle, 2 auto, 3 qsync */
				/*   1 << 14 | 120 << 7 | 1     */
				qcom,mdss-dsi-h-sync-skew = <31745>;
				/* mode: 0 normal, 1 idle, 2 auto, 3 qsync, 4 diff, 5 test */
				mi,mdss-dsi-ddic-mode = "idle";
				mi,mdss-dsi-sf-framerate = <120>;
				mi,mdss-dsi-ddic-min-framerate = <1>;
				qcom,mdss-dsi-nolp-command = [
					39 00 00 00 00 00 03 51 00 23
				];
				qcom,mdss-dsi-nolp-command-state = "dsi_hs_mode";
				qcom,mdss-dsi-nolp-command-update = <0x51 0 2>;
				qcom,mdss-dsi-timing-switch-command = [
					15 00 00 40 00 00 02 6C 00
					39 00 00 40 00 00 03 75 C0 04
					39 00 00 40 00 00 04 71 00 00 00
					39 00 00 40 00 00 03 F0 AA 16
					15 00 00 40 00 00 02 D0 03
					15 00 00 40 00 00 02 65 01
					15 00 00 40 00 00 02 D1 01
					15 00 00 40 00 00 02 D2 01
					15 00 00 40 00 00 02 65 02
					39 00 00 40 00 00 04 D2 0A 53 0F
					15 00 00 40 00 00 02 76 01
					15 00 00 40 00 00 02 77 01
					39 00 00 40 00 00 03 F0 AA 10
					15 00 00 40 00 00 02 CF 09
					39 00 00 00 00 00 03 F0 AA 00
				];
				qcom,mdss-dsi-timing-switch-command-state = "dsi_hs_mode";
				mi,mdss-dsi-timing-switch-pwm-command = [
					15 00 00 40 00 00 02 6C 02
					39 00 00 40 00 00 03 75 C0 05
					39 00 00 40 00 00 04 71 00 00 00
					39 00 00 40 00 00 03 F0 AA 16
					15 00 00 40 00 00 02 D0 03
					15 00 00 40 00 00 02 65 07
					15 00 00 40 00 00 02 D1 0B
					15 00 00 40 00 00 02 D2 01
					15 00 00 40 00 00 02 65 02
					39 00 00 40 00 00 04 D2 03 65 0F
					15 00 00 40 00 00 02 76 01
					15 00 00 40 00 00 02 77 05
					39 00 00 40 00 00 03 F0 AA 10
					15 00 00 40 00 00 02 CF 09
					39 00 00 00 00 00 03 F0 AA 00
				];
				mi,mdss-dsi-timing-switch-pwm-command-state = "dsi_hs_mode";
				qcom,mdss-dsi-on-command = [
					15 00 00 40 00 00 02 00 00
					15 00 00 40 00 00 02 03 01
					15 00 00 40 00 00 02 35 00
					15 00 00 40 00 00 02 53 20
					39 00 00 40 00 00 03 51 00 00
					15 00 00 40 00 00 02 6F 02
					15 00 00 40 00 00 02 59 00
					15 00 00 40 00 00 02 6C 00
					15 00 00 40 00 00 02 6D 00
					39 00 00 40 00 00 5F 70 11 00 00 89 30 80 0a 30 04 b0
											00 10 02 58 02 58 02 00 02 2c
											00 20 01 98 00 08 00 0c 06 67
											05 b9 18 00 10 f0 03 0c 20 00
											06 0b 0b 33 0e 1c 2a 38 46 54
											62 69 70 77 79 7b 7d 7e 01 02
											01 00 09 40 09 be 19 fc 19 fa
											19 f8 1a 38 1a 78 1a b6 2a b6
											2a f4 2a f4 4b 34 63 74 00 00 00 00 00 00
					39 00 00 40 00 00 03 FF 5A 81
					15 00 00 40 00 00 02 65 03
					15 00 00 40 00 00 02 F3 04
					15 00 00 40 00 00 02 65 05
					15 00 00 40 00 00 02 F3 48
					39 00 00 40 00 00 03 F0 AA 10
					15 00 00 40 00 00 02 65 0A
					15 00 00 40 00 00 02 EB 10
					15 00 00 40 00 00 02 72 00
					39 00 00 40 00 00 03 F0 AA 18
					15 00 00 40 00 00 02 B0 80
					39 00 00 40 00 00 03 F0 AA 00
					39 00 00 40 00 00 03 FF 5A 00
					05 00 00 00 78 00 01 11
					39 00 00 40 00 00 03 F0 AA 10
					15 00 00 40 00 00 02 65 02
					39 00 00 40 00 00 03 CF 24 13
					15 00 00 40 00 00 02 65 0B
					15 00 00 40 00 00 02 CF FF
					39 00 00 00 00 00 03 F0 AA 00
					39 00 00 40 00 00 03 F0 AA 16
					39 00 00 40 00 00 16 E3 00 01 00 00 00 00 00 00 00 00 00 00 00 00 00 00 00 00 00 00 00
					39 00 00 40 00 00 16 E4 00 03 00 00 00 00 00 00 00 00 00 00 00 00 00 00 00 00 00 00 00
					39 00 00 40 00 00 16 E5 00 04 00 00 00 00 00 00 00 00 00 00 00 00 00 00 00 00 00 00 00
					39 00 00 40 00 00 16 E6 01 03 0B 00 00 00 00 00 00 00 00 00 00 00 00 00 00 00 00 00 00
					39 00 00 40 00 00 16 E7 03 03 0B 0B 77 00 00 00 00 0E E0 00 00 00 00 00 00 00 00 00 00
					39 00 00 40 00 00 16 E8 02 0B 0B 77 00 00 00 00 00 EE 00 00 00 00 00 00 00 00 00 00 00
					39 00 00 40 00 00 16 E9 02 08 08 59 00 00 00 00 00 EE 00 00 00 00 00 00 00 00 00 00 00
					39 00 00 40 00 00 16 EA 00 0B 00 00 00 00 00 00 00 00 00 00 00 00 00 00 00 00 00 00 00
					39 00 00 40 00 00 16 EB 02 01 03 EF 00 00 00 00 00 00 00 00 00 00 00 00 00 00 00 00 00
					39 00 00 40 00 00 16 EC 00 01 00 00 00 00 00 00 00 40 00 00 00 00 00 00 00 00 00 00 00
					39 00 00 40 00 00 1F E0 F0 F1 F2 F3 F4 F5 F6 00 00 00 F0 F1 F2 F3 F4 F5 F6 00 00 00 F0 F1 F2 F3 F4 F5 F6 00 00 00
					39 00 00 40 00 00 15 ED F0 F1 F2 F3 F4 F5 F6 F7 F8 00 F0 F1 F2 F3 F4 F5 F6 F7 F8 00
					39 00 00 00 00 00 15 EE F0 F1 F2 F3 F4 F5 F6 F7 F8 00 F0 F1 F2 F3 F4 F5 F6 F7 F8 00
					//Close ELVDD LVD
					39 00 00 40 00 00 03 F0 AA 12
					15 00 00 40 00 00 02 C7 FE
					05 00 00 00 00 00 01 29
					39 00 00 40 00 00 03 F0 AA 10
					15 00 00 40 00 00 02 65 0B
					39 00 00 40 00 00 03 CF DD 79
					39 00 00 00 00 00 03 F0 AA 00
					// FD open
					39 00 00 40 00 00 03 F0 AA 10
					15 00 00 40 00 00 02 D0 A4
					15 00 00 40 00 00 02 65 04
					15 00 00 40 00 00 02 D0 E6
					15 00 00 40 00 00 02 65 13
					39 00 00 00 24 00 03 D8 02 1F
					// FD close
					39 00 00 40 00 00 03 F0 AA 10
					15 00 00 40 00 00 02 D0 84
					39 00 00 00 00 00 03 F0 AA 00
				];
				qcom,mdss-dsi-on-command-state = "dsi_lp_mode";
			};
			timing@wqhd_auto_60_to_1hz_index_7 {
				#include "dsi-panel-p2-42-0d-0b-prim-dsc-cmd-common.dtsi"
				cell-index = <7>;
				qcom,mdss-dsi-panel-framerate = <60>;
				/* ---------------------------- */
				/* | 15 - 14 | 13 - 7 | 6 - 0 | */
				/* ---------------------------- */
				/* |   mode  | sf fps | min fps| */
				/* ---------------------------- -*/
				/* mode: 1 idle, 2 auto, 3 qsync */
				/*   2 << 14 | 60 << 7 | 1     */
				qcom,mdss-dsi-h-sync-skew = <40449>;
				/* mode: 0 normal, 1 idle, 2 auto, 3 qsync, 4 diff, 5 test */
				mi,mdss-dsi-ddic-mode = "auto";
				mi,mdss-dsi-sf-framerate = <60>;
				mi,mdss-dsi-ddic-min-framerate = <1>;
				qcom,mdss-dsi-nolp-command = [
					39 00 00 00 00 00 03 51 00 23
				];
				qcom,mdss-dsi-nolp-command-state = "dsi_hs_mode";
				qcom,mdss-dsi-nolp-command-update = <0x51 0 2>;
				qcom,mdss-dsi-timing-switch-command = [
					15 00 00 40 00 00 02 6C 00
					39 00 00 40 00 00 03 75 C0 05
					39 00 00 40 00 00 04 71 00 00 00
					39 00 00 40 00 00 03 F0 AA 16
					15 00 00 40 00 00 02 D0 01
					15 00 00 40 00 00 02 65 01
					15 00 00 40 00 00 02 D1 03
					15 00 00 40 00 00 02 D2 01
					15 00 00 40 00 00 02 65 02
					39 00 00 40 00 00 04 D2 0A 53 0F
					15 00 00 40 00 00 02 76 01
					15 00 00 40 00 00 02 77 03
					39 00 00 40 00 00 03 F0 AA 10
					15 00 00 40 00 00 02 CF 09
					39 00 00 00 00 00 03 F0 AA 00
				];
				qcom,mdss-dsi-timing-switch-command-state = "dsi_hs_mode";
				mi,mdss-dsi-timing-switch-pwm-command = [
					15 00 00 40 00 00 02 6C 02
					39 00 00 40 00 00 03 75 C0 05
					39 00 00 40 00 00 04 71 00 00 00
					39 00 00 40 00 00 03 F0 AA 16
					15 00 00 40 00 00 02 D0 01
					15 00 00 40 00 00 02 65 07
					15 00 00 40 00 00 02 D1 0B
					15 00 00 40 00 00 02 D2 01
					15 00 00 40 00 00 02 65 02
					39 00 00 40 00 00 04 D2 03 65 0F
					15 00 00 40 00 00 02 76 01
					15 00 00 40 00 00 02 77 0B
					39 00 00 40 00 00 03 F0 AA 10
					15 00 00 40 00 00 02 CF 09
					39 00 00 00 00 00 03 F0 AA 00
				];
				mi,mdss-dsi-timing-switch-pwm-command-state = "dsi_hs_mode";
				qcom,mdss-dsi-on-command = [
					15 00 00 40 00 00 02 00 00
					15 00 00 40 00 00 02 03 01
					15 00 00 40 00 00 02 35 00
					15 00 00 40 00 00 02 53 20
					39 00 00 40 00 00 03 51 00 00
					15 00 00 40 00 00 02 6F 02
					15 00 00 40 00 00 02 59 00
					15 00 00 40 00 00 02 6C 00
					15 00 00 40 00 00 02 6D 00
					39 00 00 40 00 00 5F 70 11 00 00 89 30 80 0a 30 04 b0
											00 10 02 58 02 58 02 00 02 2c
											00 20 01 98 00 08 00 0c 06 67
											05 b9 18 00 10 f0 03 0c 20 00
											06 0b 0b 33 0e 1c 2a 38 46 54
											62 69 70 77 79 7b 7d 7e 01 02
											01 00 09 40 09 be 19 fc 19 fa
											19 f8 1a 38 1a 78 1a b6 2a b6
											2a f4 2a f4 4b 34 63 74 00 00 00 00 00 00
					39 00 00 40 00 00 03 FF 5A 81
					15 00 00 40 00 00 02 65 03
					15 00 00 40 00 00 02 F3 04
					15 00 00 40 00 00 02 65 05
					15 00 00 40 00 00 02 F3 48
					39 00 00 40 00 00 03 F0 AA 10
					15 00 00 40 00 00 02 65 0A
					15 00 00 40 00 00 02 EB 10
					15 00 00 40 00 00 02 72 00
					39 00 00 40 00 00 03 F0 AA 18
					15 00 00 40 00 00 02 B0 80
					39 00 00 40 00 00 03 F0 AA 00
					39 00 00 40 00 00 03 FF 5A 00
					05 00 00 00 78 00 01 11
					39 00 00 40 00 00 03 F0 AA 10
					15 00 00 40 00 00 02 65 02
					39 00 00 40 00 00 03 CF 24 13
					15 00 00 40 00 00 02 65 0B
					15 00 00 40 00 00 02 CF FF
					39 00 00 00 00 00 03 F0 AA 00
					39 00 00 40 00 00 03 F0 AA 16
					39 00 00 40 00 00 16 E3 00 01 00 00 00 00 00 00 00 00 00 00 00 00 00 00 00 00 00 00 00
					39 00 00 40 00 00 16 E4 00 03 00 00 00 00 00 00 00 00 00 00 00 00 00 00 00 00 00 00 00
					39 00 00 40 00 00 16 E5 00 04 00 00 00 00 00 00 00 00 00 00 00 00 00 00 00 00 00 00 00
					39 00 00 40 00 00 16 E6 01 03 0B 00 00 00 00 00 00 00 00 00 00 00 00 00 00 00 00 00 00
					39 00 00 40 00 00 16 E7 03 03 0B 0B 77 00 00 00 00 0E E0 00 00 00 00 00 00 00 00 00 00
					39 00 00 40 00 00 16 E8 02 0B 0B 77 00 00 00 00 00 EE 00 00 00 00 00 00 00 00 00 00 00
					39 00 00 40 00 00 16 E9 02 08 08 59 00 00 00 00 00 EE 00 00 00 00 00 00 00 00 00 00 00
					39 00 00 40 00 00 16 EA 00 0B 00 00 00 00 00 00 00 00 00 00 00 00 00 00 00 00 00 00 00
					39 00 00 40 00 00 16 EB 02 01 03 EF 00 00 00 00 00 00 00 00 00 00 00 00 00 00 00 00 00
					39 00 00 40 00 00 16 EC 00 01 00 00 00 00 00 00 00 40 00 00 00 00 00 00 00 00 00 00 00
					39 00 00 40 00 00 1F E0 F0 F1 F2 F3 F4 F5 F6 00 00 00 F0 F1 F2 F3 F4 F5 F6 00 00 00 F0 F1 F2 F3 F4 F5 F6 00 00 00
					39 00 00 40 00 00 15 ED F0 F1 F2 F3 F4 F5 F6 F7 F8 00 F0 F1 F2 F3 F4 F5 F6 F7 F8 00
					39 00 00 00 00 00 15 EE F0 F1 F2 F3 F4 F5 F6 F7 F8 00 F0 F1 F2 F3 F4 F5 F6 F7 F8 00
					//Close ELVDD LVD
					39 00 00 40 00 00 03 F0 AA 12
					15 00 00 40 00 00 02 C7 FE
					05 00 00 00 00 00 01 29
					39 00 00 40 00 00 03 F0 AA 10
					15 00 00 40 00 00 02 65 0B
					39 00 00 40 00 00 03 CF DD 79
					39 00 00 00 00 00 03 F0 AA 00
					// FD open
					39 00 00 40 00 00 03 F0 AA 10
					15 00 00 40 00 00 02 D0 A4
					15 00 00 40 00 00 02 65 04
					15 00 00 40 00 00 02 D0 E6
					15 00 00 40 00 00 02 65 13
					39 00 00 00 24 00 03 D8 02 1F
					// FD close
					39 00 00 40 00 00 03 F0 AA 10
					15 00 00 40 00 00 02 D0 84
					39 00 00 00 00 00 03 F0 AA 00
				];
				qcom,mdss-dsi-on-command-state = "dsi_lp_mode";
			};
			timing@wqhd_auto_120_to_1hz_index_8 {
				#include "dsi-panel-p2-42-0d-0b-prim-dsc-cmd-common.dtsi"
				cell-index = <8>;
				qcom,mdss-dsi-panel-framerate = <120>;
				/* ---------------------------- */
				/* | 15 - 14 | 13 - 7 | 6 - 0 | */
				/* ---------------------------- */
				/* |   mode  | sf fps | min fps| */
				/* ---------------------------- -*/
				/* mode: 1 idle, 2 auto, 3 qsync */
				/*   2 << 14 | 120 << 7 | 1     */
				qcom,mdss-dsi-h-sync-skew = <48129>;
				/* mode: 0 normal, 1 idle, 2 auto, 3 qsync, 4 diff, 5 test */
				mi,mdss-dsi-ddic-mode = "auto";
				mi,mdss-dsi-sf-framerate = <120>;
				mi,mdss-dsi-ddic-min-framerate = <1>;
				qcom,mdss-dsi-nolp-command = [
					39 00 00 00 00 00 03 51 00 23
				];
				qcom,mdss-dsi-nolp-command-state = "dsi_hs_mode";
				qcom,mdss-dsi-nolp-command-update = <0x51 0 2>;
				qcom,mdss-dsi-timing-switch-command = [
					15 00 00 40 00 00 02 6C 00
					39 00 00 40 00 00 03 75 C0 04
					39 00 00 40 00 00 04 71 00 00 00
					39 00 00 40 00 00 03 F0 AA 16
					15 00 00 40 00 00 02 D0 03
					15 00 00 40 00 00 02 65 01
					15 00 00 40 00 00 02 D1 01
					15 00 00 40 00 00 02 D2 01
					15 00 00 40 00 00 02 65 02
					39 00 00 40 00 00 04 D2 0A 53 0F
					15 00 00 40 00 00 02 76 01
					15 00 00 40 00 00 02 77 01
					39 00 00 40 00 00 03 F0 AA 10
					15 00 00 40 00 00 02 CF 09
					39 00 00 00 00 00 03 F0 AA 00
				];
				qcom,mdss-dsi-timing-switch-command-state = "dsi_hs_mode";
				mi,mdss-dsi-timing-switch-pwm-command = [
					15 00 00 40 00 00 02 6C 02
					39 00 00 40 00 00 03 75 C0 05
					39 00 00 40 00 00 04 71 00 00 00
					39 00 00 40 00 00 03 F0 AA 16
					15 00 00 40 00 00 02 D0 03
					15 00 00 40 00 00 02 65 07
					15 00 00 40 00 00 02 D1 0B
					15 00 00 40 00 00 02 D2 01
					15 00 00 40 00 00 02 65 02
					39 00 00 40 00 00 04 D2 03 65 0F
					15 00 00 40 00 00 02 76 01
					15 00 00 40 00 00 02 77 05
					39 00 00 40 00 00 03 F0 AA 10
					15 00 00 40 00 00 02 CF 09
					39 00 00 00 00 00 03 F0 AA 00
				];
				mi,mdss-dsi-timing-switch-pwm-command-state = "dsi_hs_mode";
				qcom,mdss-dsi-on-command = [
					15 00 00 40 00 00 02 00 00
					15 00 00 40 00 00 02 03 01
					15 00 00 40 00 00 02 35 00
					15 00 00 40 00 00 02 53 20
					39 00 00 40 00 00 03 51 00 00
					15 00 00 40 00 00 02 6F 02
					15 00 00 40 00 00 02 59 00
					15 00 00 40 00 00 02 6C 00
					15 00 00 40 00 00 02 6D 00
					39 00 00 40 00 00 5F 70 11 00 00 89 30 80 0a 30 04 b0
											00 10 02 58 02 58 02 00 02 2c
											00 20 01 98 00 08 00 0c 06 67
											05 b9 18 00 10 f0 03 0c 20 00
											06 0b 0b 33 0e 1c 2a 38 46 54
											62 69 70 77 79 7b 7d 7e 01 02
											01 00 09 40 09 be 19 fc 19 fa
											19 f8 1a 38 1a 78 1a b6 2a b6
											2a f4 2a f4 4b 34 63 74 00 00 00 00 00 00
					39 00 00 40 00 00 03 FF 5A 81
					15 00 00 40 00 00 02 65 03
					15 00 00 40 00 00 02 F3 04
					15 00 00 40 00 00 02 65 05
					15 00 00 40 00 00 02 F3 48
					39 00 00 40 00 00 03 F0 AA 10
					15 00 00 40 00 00 02 65 0A
					15 00 00 40 00 00 02 EB 10
					15 00 00 40 00 00 02 72 00
					39 00 00 40 00 00 03 F0 AA 18
					15 00 00 40 00 00 02 B0 80
					39 00 00 40 00 00 03 F0 AA 00
					39 00 00 40 00 00 03 FF 5A 00
					05 00 00 00 78 00 01 11
					39 00 00 40 00 00 03 F0 AA 10
					15 00 00 40 00 00 02 65 02
					39 00 00 40 00 00 03 CF 24 13
					15 00 00 40 00 00 02 65 0B
					15 00 00 40 00 00 02 CF FF
					39 00 00 00 00 00 03 F0 AA 00
					39 00 00 40 00 00 03 F0 AA 16
					39 00 00 40 00 00 16 E3 00 01 00 00 00 00 00 00 00 00 00 00 00 00 00 00 00 00 00 00 00
					39 00 00 40 00 00 16 E4 00 03 00 00 00 00 00 00 00 00 00 00 00 00 00 00 00 00 00 00 00
					39 00 00 40 00 00 16 E5 00 04 00 00 00 00 00 00 00 00 00 00 00 00 00 00 00 00 00 00 00
					39 00 00 40 00 00 16 E6 01 03 0B 00 00 00 00 00 00 00 00 00 00 00 00 00 00 00 00 00 00
					39 00 00 40 00 00 16 E7 03 03 0B 0B 77 00 00 00 00 0E E0 00 00 00 00 00 00 00 00 00 00
					39 00 00 40 00 00 16 E8 02 0B 0B 77 00 00 00 00 00 EE 00 00 00 00 00 00 00 00 00 00 00
					39 00 00 40 00 00 16 E9 02 08 08 59 00 00 00 00 00 EE 00 00 00 00 00 00 00 00 00 00 00
					39 00 00 40 00 00 16 EA 00 0B 00 00 00 00 00 00 00 00 00 00 00 00 00 00 00 00 00 00 00
					39 00 00 40 00 00 16 EB 02 01 03 EF 00 00 00 00 00 00 00 00 00 00 00 00 00 00 00 00 00
					39 00 00 40 00 00 16 EC 00 01 00 00 00 00 00 00 00 40 00 00 00 00 00 00 00 00 00 00 00
					39 00 00 40 00 00 1F E0 F0 F1 F2 F3 F4 F5 F6 00 00 00 F0 F1 F2 F3 F4 F5 F6 00 00 00 F0 F1 F2 F3 F4 F5 F6 00 00 00
					39 00 00 40 00 00 15 ED F0 F1 F2 F3 F4 F5 F6 F7 F8 00 F0 F1 F2 F3 F4 F5 F6 F7 F8 00
					39 00 00 00 00 00 15 EE F0 F1 F2 F3 F4 F5 F6 F7 F8 00 F0 F1 F2 F3 F4 F5 F6 F7 F8 00
					//Close ELVDD LVD
					39 00 00 40 00 00 03 F0 AA 12
					15 00 00 40 00 00 02 C7 FE
					05 00 00 00 00 00 01 29
					39 00 00 40 00 00 03 F0 AA 10
					15 00 00 40 00 00 02 65 0B
					39 00 00 40 00 00 03 CF DD 79
					39 00 00 00 00 00 03 F0 AA 00
					// FD open
					39 00 00 40 00 00 03 F0 AA 10
					15 00 00 40 00 00 02 D0 A4
					15 00 00 40 00 00 02 65 04
					15 00 00 40 00 00 02 D0 E6
					15 00 00 40 00 00 02 65 13
					39 00 00 00 24 00 03 D8 02 1F
					// FD close
					39 00 00 40 00 00 03 F0 AA 10
					15 00 00 40 00 00 02 D0 84
					39 00 00 00 00 00 03 F0 AA 00
				];
				qcom,mdss-dsi-on-command-state = "dsi_lp_mode";
			};
			//FOR PWM Qsync, 360hz TE
			timing@wqhd_qsync_120_to_10hz_index_9 {
				#include "dsi-panel-p2-42-0d-0b-prim-dsc-cmd-common.dtsi"
				cell-index = <9>;
				qcom,mdss-dsi-panel-framerate = <120>;
				qcom,dsi-qsync-mode-avr-step-fps = <360>;
				/* ---------------------------- */
				/* | 15 - 14 | 13 - 7 | 6 - 0 | */
				/* ---------------------------- */
				/* |   mode  | sf fps | min fps| */
				/* ---------------------------- -*/
				/* mode: 1 idle, 2 auto, 3 qsync */
				/*   3 << 14 | 120 << 7 | 10     */
				qcom,mdss-dsi-h-sync-skew = <64522>;
				/* mode: 0 normal, 1 idle, 2 auto, 3 qsync, 4 diff, 5 test */
				mi,mdss-dsi-ddic-mode = "qsync";
				mi,mdss-dsi-sf-framerate = <120>;
				mi,mdss-dsi-ddic-min-framerate = <10>;
				qcom,mdss-dsi-nolp-command = [
					39 00 00 00 00 00 03 51 00 23
				];
				qcom,mdss-dsi-nolp-command-state = "dsi_hs_mode";
				qcom,mdss-dsi-nolp-command-update = <0x51 0 2>;
				qcom,mdss-dsi-timing-switch-command = [
					15 00 00 40 00 00 02 6C 02
					39 00 00 40 00 00 03 75 C0 07
					39 00 00 40 00 00 04 71 00 00 00
					39 00 00 40 00 00 03 F0 AA 16
					15 00 00 40 00 00 02 D0 01
					15 00 00 40 00 00 02 65 07
					15 00 00 40 00 00 02 D1 0B
					15 00 00 40 00 00 02 D2 02
					15 00 00 40 00 00 02 76 00
					15 00 00 40 00 00 02 77 00
					39 00 00 40 00 00 03 F0 AA 10
					15 00 00 40 00 00 02 CF 17
					39 00 00 00 00 00 03 F0 AA 00
				];
				qcom,mdss-dsi-timing-switch-command-state = "dsi_hs_mode";
				mi,mdss-dsi-timing-switch-pwm-command = [
					15 00 00 40 00 00 02 6C 02
					39 00 00 40 00 00 03 75 C0 07
					39 00 00 40 00 00 04 71 00 00 00
					39 00 00 40 00 00 03 F0 AA 16
					15 00 00 40 00 00 02 D0 01
					15 00 00 40 00 00 02 65 07
					15 00 00 40 00 00 02 D1 0B
					15 00 00 40 00 00 02 D2 02
					15 00 00 40 00 00 02 76 00
					15 00 00 40 00 00 02 77 00
					39 00 00 40 00 00 03 F0 AA 10
					15 00 00 40 00 00 02 CF 17
					39 00 00 00 00 00 03 F0 AA 00
				];
				mi,mdss-dsi-timing-switch-pwm-command-state = "dsi_hs_mode";
				qcom,mdss-dsi-on-command = [
					15 00 00 40 00 00 02 00 00
					15 00 00 40 00 00 02 03 01
					15 00 00 40 00 00 02 35 00
					15 00 00 40 00 00 02 53 20
					39 00 00 40 00 00 03 51 00 00
					15 00 00 40 00 00 02 6F 02
					15 00 00 40 00 00 02 59 00
					15 00 00 40 00 00 02 6C 00
					15 00 00 40 00 00 02 6D 00
					39 00 00 40 00 00 5F 70 11 00 00 89 30 80 0a 30 04 b0
											00 10 02 58 02 58 02 00 02 2c
											00 20 01 98 00 08 00 0c 06 67
											05 b9 18 00 10 f0 03 0c 20 00
											06 0b 0b 33 0e 1c 2a 38 46 54
											62 69 70 77 79 7b 7d 7e 01 02
											01 00 09 40 09 be 19 fc 19 fa
											19 f8 1a 38 1a 78 1a b6 2a b6
											2a f4 2a f4 4b 34 63 74 00 00 00 00 00 00
					39 00 00 40 00 00 03 FF 5A 81
					15 00 00 40 00 00 02 65 03
					15 00 00 40 00 00 02 F3 04
					15 00 00 40 00 00 02 65 05
					15 00 00 40 00 00 02 F3 48
					39 00 00 40 00 00 03 F0 AA 10
					15 00 00 40 00 00 02 65 0A
					15 00 00 40 00 00 02 EB 10
					15 00 00 40 00 00 02 72 00
					39 00 00 40 00 00 03 F0 AA 18
					15 00 00 40 00 00 02 B0 80
					39 00 00 40 00 00 03 F0 AA 00
					39 00 00 40 00 00 03 FF 5A 00
					05 00 00 00 78 00 01 11
					39 00 00 40 00 00 03 F0 AA 10
					15 00 00 40 00 00 02 65 02
					39 00 00 40 00 00 03 CF 24 13
					15 00 00 40 00 00 02 65 0B
					15 00 00 40 00 00 02 CF FF
					39 00 00 00 00 00 03 F0 AA 00
					39 00 00 40 00 00 03 F0 AA 16
					39 00 00 40 00 00 16 E3 00 01 00 00 00 00 00 00 00 00 00 00 00 00 00 00 00 00 00 00 00
					39 00 00 40 00 00 16 E4 00 03 00 00 00 00 00 00 00 00 00 00 00 00 00 00 00 00 00 00 00
					39 00 00 40 00 00 16 E5 00 04 00 00 00 00 00 00 00 00 00 00 00 00 00 00 00 00 00 00 00
					39 00 00 40 00 00 16 E6 01 03 0B 00 00 00 00 00 00 00 00 00 00 00 00 00 00 00 00 00 00
					39 00 00 40 00 00 16 E7 03 03 0B 0B 77 00 00 00 00 0E E0 00 00 00 00 00 00 00 00 00 00
					39 00 00 40 00 00 16 E8 02 0B 0B 77 00 00 00 00 00 EE 00 00 00 00 00 00 00 00 00 00 00
					39 00 00 40 00 00 16 E9 02 08 08 59 00 00 00 00 00 EE 00 00 00 00 00 00 00 00 00 00 00
					39 00 00 40 00 00 16 EA 00 0B 00 00 00 00 00 00 00 00 00 00 00 00 00 00 00 00 00 00 00
					39 00 00 40 00 00 16 EB 02 01 03 EF 00 00 00 00 00 00 00 00 00 00 00 00 00 00 00 00 00
					39 00 00 40 00 00 16 EC 00 01 00 00 00 00 00 00 00 40 00 00 00 00 00 00 00 00 00 00 00
					39 00 00 40 00 00 1F E0 F0 F1 F2 F3 F4 F5 F6 00 00 00 F0 F1 F2 F3 F4 F5 F6 00 00 00 F0 F1 F2 F3 F4 F5 F6 00 00 00
					39 00 00 40 00 00 15 ED F0 F1 F2 F3 F4 F5 F6 F7 F8 00 F0 F1 F2 F3 F4 F5 F6 F7 F8 00
					39 00 00 00 00 00 15 EE F0 F1 F2 F3 F4 F5 F6 F7 F8 00 F0 F1 F2 F3 F4 F5 F6 F7 F8 00
					//Close ELVDD LVD
					39 00 00 40 00 00 03 F0 AA 12
					15 00 00 40 00 00 02 C7 FE
					05 00 00 00 00 00 01 29
					39 00 00 40 00 00 03 F0 AA 10
					15 00 00 40 00 00 02 65 0B
					39 00 00 40 00 00 03 CF DD 79
					39 00 00 00 00 00 03 F0 AA 00
					// FD open
					39 00 00 40 00 00 03 F0 AA 10
					15 00 00 40 00 00 02 D0 A4
					15 00 00 40 00 00 02 65 04
					15 00 00 40 00 00 02 D0 E6
					15 00 00 40 00 00 02 65 13
					39 00 00 00 24 00 03 D8 02 1F
					// FD close
					39 00 00 40 00 00 03 F0 AA 10
					15 00 00 40 00 00 02 D0 84
					39 00 00 00 00 00 03 F0 AA 00
				];
				qcom,mdss-dsi-on-command-state = "dsi_lp_mode";
			};
		};
	};
};
&dsi_p2_42_0d_0b_prim_dsc_cmd {
	qcom,panel-supply-entries = <&dsi_panel_pwr_supply_p2_0b>;
	qcom,mdss-dsi-bl-pmic-control-type = "bl_ctrl_dcs";
	qcom,mdss-dsi-bl-min-level = <7>;
	qcom,mdss-dsi-bl-max-level = <16383>;
	qcom,bl-dsc-cmd-state = "dsi_hs_mode";
	qcom,mdss-brightness-max-level = <16383>;
	qcom,mdss-brightness-init-level = <916>;
	qcom,platform-reset-gpio = <&tlmm 98 0>;
	qcom,platform-pmic-reset-gpio = <&tlmm 171 0>;

	mi,panel-id = <0x00005032 0x50420D0B>;
	mi,panel-on-dimming-delay = <120>;
	mi,dc-feature-enabled;

	/* IRQF_ONESHOT | IRQF_TRIGGER_HEIGH */
	mi,esd-err-irq-gpio = <&tlmm 97 0x2004>;
	mi,esd-err-irq-gpio-flag = <0x2004>;

	mi,mdss-dsi-panel-wp-read-command = [06 01 00 00 00 00 01 A3];
	mi,mdss-dsi-panel-wp-read-command-state = "dsi_hs_mode";
	mi,mdss-dsi-panel-wp-read-pre-tx-command = [39 00 00 00 00 00 02 6F EF];
	mi,mdss-dsi-panel-wp-read-pre-tx-command-state = "dsi_hs_mode";
	mi,mdss-dsi-panel-wp-read-length = <8>;

	mi,mdss-dsi-panel-cell-id-read-command = [06 01 00 00 00 00 01 EB];
	mi,mdss-dsi-panel-cell-id-read-pre-tx-command = [
		39 00 00 40 00 00 06 F0 55 AA 52 08 00
		39 00 00 00 00 00 02 EA 10];
	mi,mdss-dsi-panel-cell-id-read-pre-tx-command-state = "dsi_hs_mode";
	mi,mdss-dsi-panel-cell-id-read-command-state = "dsi_hs_mode";
	mi,mdss-dsi-panel-cell-id-read-length = <13>;

	mi,mdss-dsi-fac-bl-max-level = <8191>;
	mi,mdss-fac-brightness-max-level = <8191>;
	mi,flatmode-status-check-enabled;
	mi,mdss-dsi-panel-flatmode-status-command = [
			06 01 00 01 00 00 01 5F
	];
	mi,mdss-dsi-panel-flatmode-status-command-state = "dsi_hs_mode";
	mi,mdss-dsi-panel-flatmode-status-read-length = <1>;
	mi,mdss-dsi-panel-flatmode-on-status-value = <0x00>;

	mi,doze-hbm-dbv-level = <412>;
	mi,doze-lbm-dbv-level = <35>;
	mi,ddic-round-corner-enabled;

	mi,max-brightness-normal = <8191>;

	mi,panel-build-id-read-needed;
	mi,panel-build-id-read-length = <1>;
	mi,mdss-dsi-panel-build-id-read-command = [06 01 00 00 00 00 01 DA];
	mi,mdss-dsi-panel-build-id-read-command-state = "dsi_hs_mode";

	qcom,ulps-enabled;
	qcom,dsi-select-clocks = "pll_byte_clk0", "pll_dsi_clk0";
	qcom,mdss-dsi-clk-strength = <0xFF>;
};
